# EFR32BG22L122F352GM32 register map
Vendor: Silicon Labs; Series: EFR32; File version: F
Registers are 32-bit, read-write, reset 0x0 unless marked. A register's access mark holds for its fields unless they carry their own. Offsets are from the block's base; [hi:lo] are bit positions; {n}, {i} and the like mark numbered series.

## SMU_NS_CFGNS — SMU_NS_CFGNS Registers
Base 0x5400C000
Same registers: SMU_S_CFGNS 0x4400C000
0x04 NSSTATUS ro — Register for status flags.
  [0] SMUNSLOCK — SMUNS Lock Status
    0=UNLOCKED (SMUNSLOCK Unlocked); 1=LOCKED (SMUNSLOCK Locked)
0x08 NSLOCK wo — Register used to lock/unlock access to the register file.
  [23:0] SMUNSLOCKKEY — SMU Non-Secure Lock/Key
    0xACCE55=UNLOCK (Unlocks Registers)
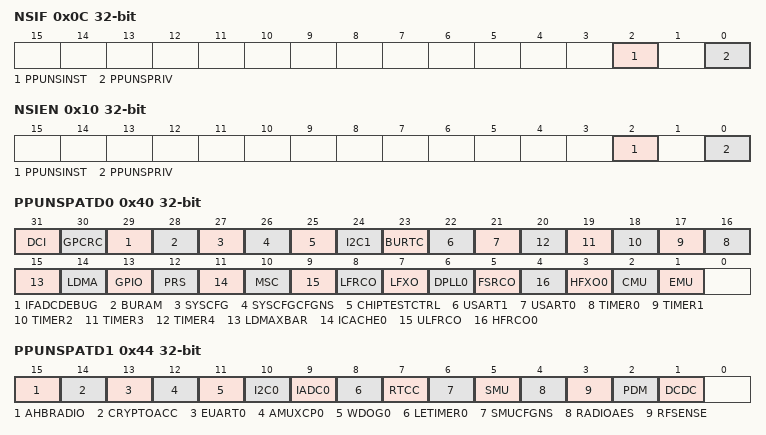
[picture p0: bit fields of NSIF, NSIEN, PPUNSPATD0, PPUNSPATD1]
0x0C NSIF — Register for interrupt status flags.
  [2] PPUNSINST — PPUNS Instruction Interrupt Flag
  [0] PPUNSPRIV — PPUNS Privilege Interrupt Flag
0x10 NSIEN — Register used for enabling/disabling interrupts.
  [2] PPUNSINST — PPUNS Instruction Interrupt Enable
  [0] PPUNSPRIV — PPUNS Privilege Interrupt Enable
0x40 PPUNSPATD0 — Set peripheral bits to 1 to mark as privileged access only.
  [31] DCI — DCI Privileged Access
  [30] GPCRC — GPCRC Privileged Access
  [29] IFADCDEBUG — IFADCDEBUG Privileged Access
  [28] BURAM — BURAM Privileged Access
  [27] SYSCFG — SYSCFG Privileged Access
  [26] SYSCFGCFGNS — SYSCFGCFGNS Privileged Access
  [25] CHIPTESTCTRL — CHIPTESTCTRL Privileged Access
  [24] I2C1 — I2C1 Privileged Access
  [23] BURTC — BURTC Privileged Access
  [22] USART1 — USART1 Privileged Access
  [21] USART0 — USART0 Privileged Access
  [n+16] TIMER{n} (n=0..4) — TIMER{n} Privileged Access
  [15] LDMAXBAR — LDMAXBAR Privileged Access
  [14] LDMA — LDMA Privileged Access
  [13] GPIO — GPIO Privileged Access
  [12] PRS — PRS Privileged Access
  [11] ICACHE0 — ICACHE0 Privileged Access
  [10] MSC — MSC Privileged Access
  [9] ULFRCO — ULFRCO Privileged Access
  [8] LFRCO — LFRCO Privileged Access
  [7] LFXO — LFXO Privileged Access
  [6] DPLL0 — DPLL0 Privileged Access
  [5] FSRCO — FSRCO Privileged Access
  [4] HFRCO0 — HFRCO0 Privileged Access
  [3] HFXO0 — HFXO0 Privileged Access
  [2] CMU — CMU Privileged Access
  [1] EMU — EMU Privileged Access
0x44 PPUNSPATD1 — Set peripheral bits to 1 to mark as privileged access only.
  [15] AHBRADIO — AHBRADIO Privileged Access
  [14] CRYPTOACC — CRYPTOACC Privileged Access
  [13] EUART0 — EUART0 Privileged Access
  [12] AMUXCP0 — AMUXCP0 Privileged Access
  [11] WDOG0 — WDOG0 Privileged Access
  [10] I2C0 — I2C0 Privileged Access
  [9] IADC0 — IADC0 Privileged Access
  [8] LETIMER0 — LETIMER0 Privileged Access
  [7] RTCC — RTCC Privileged Access
  [6] SMUCFGNS — SMUCFGNS Privileged Access
  [5] SMU — SMU Privileged Access
  [4] RADIOAES — RADIOAES Privileged Access
  [3] RFSENSE — RFSENSE Privileged Access
  [2] PDM — PDM Privileged Access
  [1] DCDC — DCDC Privileged Access
0x140 PPUNSFS ro — Read this register to query the fault status.
  [7:0] PPUFSPERIPHID — Peripheral ID
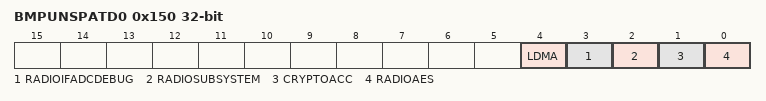
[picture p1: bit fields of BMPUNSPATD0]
0x150 BMPUNSPATD0 — Write to set BMPU priveledged attributes.
  [4] LDMA — MCU LDMA privileged mode
  [3] RADIOIFADCDEBUG — RADIO IFADC debug privileged mode
  [2] RADIOSUBSYSTEM — RADIO subsystem manager privileged mode
  [1] CRYPTOACC — CRYPTOACC DMA privileged mode
  [0] RADIOAES — RADIO AES DMA privileged mode

## SYSCFG_NS_CFGNS — SYSCFG_NS_CFGNS Registers
Base 0x50078000
Same registers: SYSCFG_S_CFGNS 0x40078000
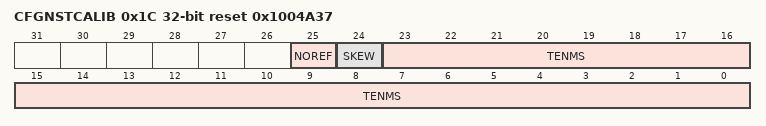
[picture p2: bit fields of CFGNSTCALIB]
0x1C CFGNSTCALIB reset 0x1004A37 — Configure to define the system tick for the M33.
  [25] NOREF — No Reference
    0=REF (Reference clock is implemented); 1=NOREF (Reference clock is not implemented)
  [24] SKEW
  [23:0] TENMS — Ten Milliseconds
0x600 ROOTNSDATA0 — Generic data space for user to pass to root, e.g., address of struct in mem
  [31:0] DATA
0x604 ROOTNSDATA1 — Generic data space for user to pass to root, e.g., address of struct in mem
  [31:0] DATA

## ULFRCO_NS — ULFRCO_NS Registers
Base 0x50028000
Same registers: ULFRCO_S 0x40028000
0x00 IPVERSION ro
  [31:0] IPVERSION — ULFRCO IP version
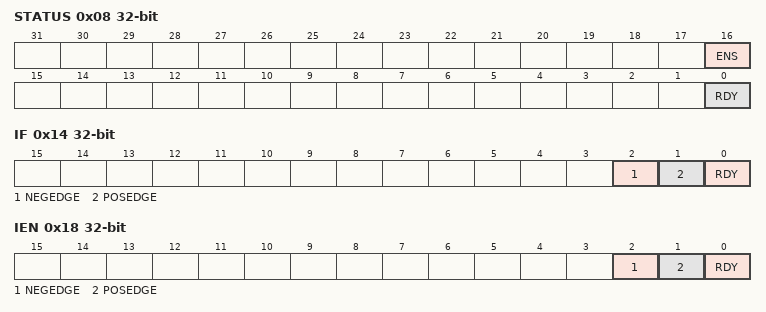
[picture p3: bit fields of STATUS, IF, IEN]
0x08 STATUS ro
  [16] ENS — Enable Status
  [0] RDY — Ready Status
0x14 IF
  [2] NEGEDGE — Negative Edge Interrupt Flag
  [1] POSEDGE — Positive Edge Interrupt Flag
  [0] RDY — Ready Interrupt Flag
0x18 IEN
  [2] NEGEDGE — Enable Negative Edge Interrupt
  [1] POSEDGE — Enable Positive Edge Interrupt
  [0] RDY — Enable Ready Interrupt

## WDOG0_NS — WDOG0_NS Registers
Base 0x5A018000
Same registers: WDOG0_S 0x4A018000
0x00 IPVERSION ro
0x04 EN
  [0] EN — Module Enable
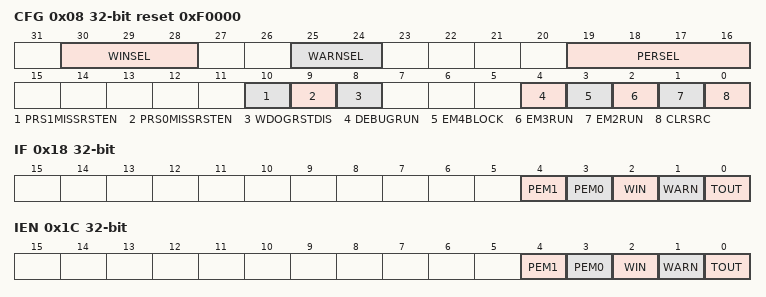
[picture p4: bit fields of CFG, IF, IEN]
0x08 CFG reset 0xF0000
  [30:28] WINSEL — WDOG Illegal Window Select
    0=DIS (Disabled.); 1=SEL1 (Window timeout is 12.5% of the Timeout.); 2=SEL2 (Window timeout is 25% of the Timeout.); 3=SEL3 (Window timeout is 37.5% of the Timeout.); 4=SEL4 (Window timeout is 50% of the Timeout.); 5=SEL5 (Window timeout is 62.5% of the Timeout.); 6=SEL6 (Window timeout is 75.5% of the Timeout.); 7=SEL7 (Window timeout is 87.5% of the Timeout.)
  [25:24] WARNSEL — WDOG Warning Period Select
    0=DIS (Disable); 1=SEL1 (Warning timeout is 25% of the Timeout.); 2=SEL2 (Warning timeout is 50% of the Timeout.); 3=SEL3 (Warning timeout is 75% of the Timeout.)
  [19:16] PERSEL — WDOG Timeout Period Select
    0=SEL0 (Timeout period of 9 wdog cycles); 1=SEL1 (Timeout period of 17 wdog cycles); 2=SEL2 (Timeout period of 33 wdog cycles); 3=SEL3 (Timeout period of 65 wdog cycles); 4=SEL4 (Timeout period of 129 wdog cycles); 5=SEL5 (Timeout period of 257 wdog cycles); 6=SEL6 (Timeout period of 513 wdog cycles); 7=SEL7 (Timeout period of 1k wdog cycles); 8=SEL8 (Timeout period of 2k wdog cycles); 9=SEL9 (Timeout period of 4k wdog cycles); 10=SEL10 (Timeout period of 8k wdog cycles); 11=SEL11 (Timeout period of 16k wdog cycles); 12=SEL12 (Timeout period of 32k wdog cycles); 13=SEL13 (Timeout period of 64k wdog cycles); 14=SEL14 (Timeout period of 128k wdog cycles); 15=SEL15 (Timeout period of 256k wdog cycles)
  [10] PRS1MISSRSTEN — PRS Src1 Missing Event WDOG Reset
  [9] PRS0MISSRSTEN — PRS Src0 Missing Event WDOG Reset
  [8] WDOGRSTDIS — WDOG Reset Disable
    0=EN (A timeout will cause a WDOG reset); 1=DIS (A timeout will not cause a WDOG reset)
  [4] DEBUGRUN — Debug Mode Run
    0=DISABLE (WDOG timer is frozen in debug mode); 1=ENABLE (WDOG timer is running in debug mode)
  [3] EM4BLOCK
    0=DISABLE (EM4 can be entered by software. See EMU for detailed description.); 1=ENABLE (EM4 cannot be entered by software.)
  [2] EM3RUN
    0=DISABLE (WDOG timer is frozen in EM3.); 1=ENABLE (WDOG timer is running in EM3.)
  [1] EM2RUN
    0=DISABLE (WDOG timer is frozen in EM2.); 1=ENABLE (WDOG timer is running in EM2.)
  [0] CLRSRC — WDOG Clear Source
    0=SW (A write to the clear bit will clear the WDOG counter); 1=PRSSRC0 (A rising edge on the PRS Source 0 will clear the WDOG counter)
0x0C CMD wo
  [0] CLEAR — WDOG Timer Clear
    0=UNCHANGED (WDOG timer is unchanged.); 1=CLEARED (WDOG timer is cleared to 0.)
0x14 STATUS ro
  [31] LOCK — WDOG Configuration Lock Status
    0=UNLOCKED (All WDOG lockable registers are unlocked.); 1=LOCKED (All WDOG lockable registers are locked.)
0x18 IF
  [4] PEM1 — PRS Src1 Event Missing Interrupt Flag
  [3] PEM0 — PRS Src0 Event Missing Interrupt Flag
  [2] WIN — WDOG Window Interrupt Flag
  [1] WARN — WDOG Warning Timeout Interrupt Flag
  [0] TOUT — WDOG Timeout Interrupt Flag
0x1C IEN
  [4] PEM1 — PRS Src1 Event Missing Interrupt Enable
  [3] PEM0 — PRS Src0 Event Missing Interrupt Enable
  [2] WIN — WDOG Window Interrupt Enable
  [1] WARN — WDOG Warning Timeout Interrupt Enable
  [0] TOUT — WDOG Timeout Interrupt Enable
0x20 LOCK wo reset 0xABE8
  [15:0] LOCKKEY — WDOG Configuration Lock
    0=LOCK (Lock WDOG lockable registers); 0xABE8=UNLOCK (Unlock WDOG lockable registers)
0x24 SYNCBUSY ro
  [0] CMD — Sync Busy for Cmd Register
